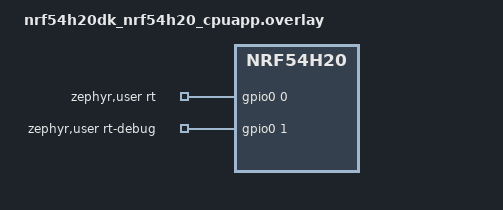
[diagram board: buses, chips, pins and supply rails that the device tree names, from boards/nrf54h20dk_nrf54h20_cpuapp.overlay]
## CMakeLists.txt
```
#
# Copyright (c) 2026 Nordic Semiconductor
#
# SPDX-License-Identifier: LicenseRef-Nordic-5-Clause
#
cmake_minimum_required(VERSION 3.20.0)

find_package(Zephyr REQUIRED HINTS $ENV{ZEPHYR_BASE})
project(rt_framework)

target_include_directories(app PRIVATE include)

# NORDIC SDK APP START
target_sources(app PRIVATE
  src/main.c
  src/rt_framework.c
  src/rt_fastpath.c
)
# NORDIC SDK APP END
```

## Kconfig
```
#
# Copyright (c) 2026 Nordic Semiconductor
#
# SPDX-License-Identifier: LicenseRef-Nordic-5-Clause
#

mainmenu "App-domain RT framework"

config RT_FW_MIN_PERIOD_US
	int "Minimum accepted RT toggle period (us)"
	default 10
	help
	  Lower bound for rt_fw_set_period_us(). Periods below this are rejected
	  rather than clamped. Guards against configuring an extremely high RT
	  tick rate that would saturate the CPU (and, on SoCs where MPSL shares
	  the application core, interfere with radio timing).

config RT_FW_MAX_PERIOD_US
	int "Maximum accepted RT toggle period (us)"
	default 1000000
	help
	  Upper bound for rt_fw_set_period_us(). The RT period is also the
	  control-plane polling interval, so this bounds the worst-case latency
	  of a subsequent stop/reconfigure command to one period.

config RT_FW_EGU_IRQ_PRIO
	int "EGU (data-plane) interrupt priority"
	depends on RT_FW_DATA_PLANE
	default 5
	help
	  Zephyr (non-ZLI) interrupt priority for the EGU interrupt that drains
	  the RT -> Zephyr event ring. Must stay below the ZLI level and is
	  SoC/board dependent. Override it per target if needed.

config RT_FW_DATA_PLANE
	bool "Enable RT -> Zephyr data plane (EGU + event ring)"
	default n
	help
	  When enabled, the RT component pushes events into a single-producer /
	  single-consumer ring in shared RAM and triggers EGU. The EGU interrupt
	  runs at a normal (non-ZLI) Zephyr priority and schedules a work item
	  that drains the ring. Demonstrates the RT -> Zephyr notification path
	  without using Zephyr primitives in the timing-critical path.

config RT_FW_SHARED_DMA_VISIBLE
	bool "Keep the RT event buffer cache-coherent for a DMA/other-master observer"
	depends on RT_FW_DATA_PLANE
	default n
	help
	  Opt-in for the case where the unidirectional RT->Zephyr event payload is
	  also observed by another bus master (a DMA engine or another core),
	  rather than only by the Zephyr threads on the application core.

	  When enabled, the event entries are aligned and padded to whole data
	  cache line(s) and rt_shared.h performs explicit cache maintenance:
	  sys_cache_data_flush_range() after the producer writes an entry and
	  sys_cache_data_invd_range() before the consumer reads it. This is the
	  same cache-maintenance pattern Zephyr's DMM uses for DMA buffers and
	  keeps the buffer coherent without placing it in non-cacheable memory.

	  This option only handles cache coherency. Exposing the buffer to a real
	  external master additionally requires mapping/placing it into that
	  master's address view, e.g. via a devicetree "zephyr,memory-region" with
	  ATTR_MPU_RAM_NOCACHE (board-specific). See the sample README.

	  Leave this disabled for the default app-core ISR <-> thread model: the
	  shared data cache is self-coherent there and ordering barriers alone are
	  sufficient, even on cached SoCs such as nRF54H20. Note that the cache
	  maintenance runs inside the ZLI, so it adds to the RT ISR time budget and
	  is not part of the minimal BLE-coexistence fast path.

config RT_FW_ISR_TEST_LOAD
	bool "Inject an artificial busy-loop load into the RT ZLI ISR"
	default n
	help
	  Adds a controlled busy-loop to the RT zero-latency ISR. Used to study
	  how a longer RT ISR affects BLE timing and to establish the RT ISR time
	  budget. This matters most on SoCs where MPSL/radio ISRs share the
	  application core (e.g. nRF54L), where the ZLI runs at the same NVIC
	  priority as the radio ISRs.

config RT_FW_ISR_TEST_LOAD_CYCLES
	int "Number of NOP iterations for the RT ISR test load"
	depends on RT_FW_ISR_TEST_LOAD
	default 100
	help
	  Number of NOP iterations executed inside the RT ZLI ISR when
	  RT_FW_ISR_TEST_LOAD is enabled.

config RT_FW_DEBUG_PIN
	bool "Drive a debug GPIO high for the duration of the RT ISR"
	default n
	help
	  Drives a second RT-owned GPIO high on ISR entry and low on ISR exit,
	  so the RT ISR execution time can be measured directly with a logic
	  analyzer or oscilloscope.

source "Kconfig.zephyr"
```

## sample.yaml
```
sample:
  description: App-domain real-time framework (TIMER + ZLI + GPIO + control plane)
  name: App-domain RT framework

tests:
  # nRF54L: single-core SoC, MPSL shares the application core. BLE runs as the
  # coexistence load.
  sample.rt_framework:
    sysbuild: false
    build_only: true
    tags:
      - bluetooth
    platform_allow:
      - nrf54lm20dk/nrf54lm20b/cpuapp
    integration_platforms:
      - nrf54lm20dk/nrf54lm20b/cpuapp

  sample.rt_framework.data_plane:
    sysbuild: false
    build_only: true
    tags:
      - bluetooth
    platform_allow:
      - nrf54lm20dk/nrf54lm20b/cpuapp
    integration_platforms:
      - nrf54lm20dk/nrf54lm20b/cpuapp
    extra_configs:
      - CONFIG_RT_FW_DATA_PLANE=y

  # nRF54H20: multi-core SoC with a managed data cache. The RT component still
  # runs only on the application core. The radio/MPSL live on the radio core, so
  # the BLE coexistence load is not built here (single app-core image).
  sample.rt_framework.nrf54h20:
    sysbuild: true
    build_only: true
    platform_allow:
      - nrf54h20dk/nrf54h20/cpuapp
    integration_platforms:
      - nrf54h20dk/nrf54h20/cpuapp

  sample.rt_framework.nrf54h20.data_plane:
    sysbuild: true
    build_only: true
    platform_allow:
      - nrf54h20dk/nrf54h20/cpuapp
    integration_platforms:
      - nrf54h20dk/nrf54h20/cpuapp
    extra_configs:
      - CONFIG_RT_FW_DATA_PLANE=y

  # Build coverage for the explicit cache-maintenance path (sys_cache_*) on a
  # target that has a data cache. Verifies the code and the cache-line
  # alignment asserts compile. Actual cross-master visibility additionally
  # needs board-specific memory placement (see README).
  sample.rt_framework.nrf54h20.dma_visible:
    sysbuild: true
    build_only: true
    platform_allow:
      - nrf54h20dk/nrf54h20/cpuapp
    integration_platforms:
      - nrf54h20dk/nrf54h20/cpuapp
    extra_configs:
      - CONFIG_RT_FW_DATA_PLANE=y
      - CONFIG_RT_FW_SHARED_DMA_VISIBLE=y
```

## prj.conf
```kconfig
#
# Copyright (c) 2026 Nordic Semiconductor
#
# SPDX-License-Identifier: LicenseRef-Nordic-5-Clause
#
CONFIG_NCS_SAMPLES_DEFAULTS=y

# BLE peripheral acts as the "coexistence load" so MPSL/SDC and the radio
# are active while the RT component runs from a zero-latency interrupt.
CONFIG_BT=y
CONFIG_BT_PERIPHERAL=y
CONFIG_BT_DEVICE_NAME="Nordic_RT_FW"
CONFIG_BT_LBS=y
CONFIG_DK_LIBRARY=y

# The RT fast path depends on Zero-latency IRQs.
CONFIG_ZERO_LATENCY_IRQS=y

# Runtime control plane is exposed through the shell.
CONFIG_SHELL=y

CONFIG_SYSTEM_WORKQUEUE_STACK_SIZE=2048

# NOTE: the RT fast path drives TIMER directly through the nrfx HAL and
# installs its own IRQ_DIRECT_CONNECT zero-latency handler.
# The nrfx_timer driver is intentionally NOT enabled, because its
# event dispatcher is incompatible with a minimal ZLI ISR.
```

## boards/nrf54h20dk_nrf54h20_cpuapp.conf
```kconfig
#
# Copyright (c) 2026 Nordic Semiconductor
#
# SPDX-License-Identifier: LicenseRef-Nordic-5-Clause
#
# On nRF54H20 the Bluetooth controller runs on the radio core. This sample is a
# single application-core image, so the optional BLE coexistence load is
# disabled here. The RT mechanism (timer + ZLI + GPIO + control/data plane) is
# exercised on its own. The coexistence scenario is demonstrated on the nRF54L
# target where MPSL shares the application core.
#
CONFIG_BT=n
CONFIG_BT_PERIPHERAL=n
CONFIG_BT_LBS=n
```

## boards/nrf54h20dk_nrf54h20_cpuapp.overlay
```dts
/*
 * Copyright (c) 2026 Nordic Semiconductor
 *
 * SPDX-License-Identifier: LicenseRef-Nordic-5-Clause
 *
 * Resource binding and ownership for the app-domain RT framework on the
 * nRF54H20 application core:
 *  - The RT time base / signaling use global-domain instances owned by the
 *    application core (timer130, egu130).
 *  - On nRF54H20 the Bluetooth controller / MPSL run on the radio core, so the
 *    application-core ZLI does NOT share its NVIC priority with radio ISRs.
 *  - Application-core ownership of a global peripheral driven directly through
 *    the nrfx HAL is expressed with status = "reserved": the build routes the
 *    IRQ and assigns ownership to cpuapp, but instantiates no Zephyr driver.
 */

#include <zephyr/dt-bindings/gpio/gpio.h>

/ {
	aliases {
		rt-timer = &timer130;
		rt-egu = &egu130;
	};

	zephyr,user {
		/* Free P0 connector pins. Wire a probe here to observe the RT path.
		 * Re-map to suit the actual board wiring.
		 */
		rt-gpios = <&gpio0 0 GPIO_ACTIVE_HIGH>;
		rt-debug-gpios = <&gpio0 1 GPIO_ACTIVE_HIGH>;
	};
};

/* Owned by the RT component, driven directly via the nrfx HAL. */
&timer130 {
	status = "reserved";
};

&egu130 {
	status = "reserved";
};

&gpio0 {
	status = "okay";
};
```

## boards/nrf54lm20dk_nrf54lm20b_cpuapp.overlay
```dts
/*
 * Copyright (c) 2026 Nordic Semiconductor
 *
 * SPDX-License-Identifier: LicenseRef-Nordic-5-Clause
 *
 * Resource binding and ownership for the app-domain RT framework on the
 * nRF54LM20 application core.
 *
 * The RT component selects its resources through the aliases / zephyr,user
 * properties below and drives them directly via the nrfx HAL. TIMER20 and
 * EGU20 are therefore kept "disabled" so no Zephyr/nrfx driver claims them:
 * this is the explicit ownership boundary between Zephyr and the RT component.
 *
 * On nRF54L, MPSL reserves TIMER10 and runs its radio ISRs at the single ZLI
 * priority on this same core, so TIMER20 / EGU20 are chosen as free instances.
 * Re-verify the per-SoC MPSL reservations when porting to another target.
 */

#include <zephyr/dt-bindings/gpio/gpio.h>

/ {
	aliases {
		rt-timer = &timer20;
		rt-egu = &egu20;
	};

	zephyr,user {
		/* P1.04: free connector pin toggled by the RT ISR. */
		rt-gpios = <&gpio1 4 GPIO_ACTIVE_HIGH>;
		/* P1.05: optional pin driven high for the RT ISR duration. */
		rt-debug-gpios = <&gpio1 5 GPIO_ACTIVE_HIGH>;
	};
};

&timer20 {
	status = "disabled";
};

&egu20 {
	status = "disabled";
};
```

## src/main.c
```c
/*
 * Copyright (c) 2026 Nordic Semiconductor
 *
 * SPDX-License-Identifier: LicenseRef-Nordic-5-Clause
 */

/*
 * App-domain RT framework - Zephyr application.
 *
 * Brings up:
 *  - the RT component (timer + zero-latency ISR toggling the RT GPIO),
 *  - optionally (CONFIG_BT) a BLE peripheral (LBS) that keeps MPSL/SDC and the
 *    radio active so the ZLI vs MPSL coexistence can be observed on SoCs where
 *    the radio shares the application core,
 *  - a shell command set ("rt ...") that exercises the control plane at
 *    runtime.
 */

#include <errno.h>
#include <zephyr/kernel.h>
#include <zephyr/sys/printk.h>
#include <zephyr/shell/shell.h>

#if defined(CONFIG_BT)
#include <zephyr/bluetooth/bluetooth.h>
#include <zephyr/bluetooth/hci.h>
#include <zephyr/bluetooth/conn.h>
#include <zephyr/bluetooth/uuid.h>
#include <zephyr/bluetooth/gatt.h>
#include <bluetooth/services/lbs.h>
#endif

#include <dk_buttons_and_leds.h>

#include "rt_framework.h"

#define RUN_STATUS_LED         DK_LED1
#define CON_STATUS_LED         DK_LED2
#define RT_EVENT_LED           DK_LED3
#define RUN_LED_BLINK_INTERVAL 1000

#if defined(CONFIG_BT)
#define DEVICE_NAME     CONFIG_BT_DEVICE_NAME
#define DEVICE_NAME_LEN (sizeof(DEVICE_NAME) - 1)

static struct k_work adv_work;

static const struct bt_data ad[] = {
	BT_DATA_BYTES(BT_DATA_FLAGS, (BT_LE_AD_GENERAL | BT_LE_AD_NO_BREDR)),
	BT_DATA(BT_DATA_NAME_COMPLETE, DEVICE_NAME, DEVICE_NAME_LEN),
};

static const struct bt_data sd[] = {
	BT_DATA_BYTES(BT_DATA_UUID128_ALL, BT_UUID_LBS_VAL),
};

static void adv_work_handler(struct k_work *work)
{
	int err;

	ARG_UNUSED(work);

	err = bt_le_adv_start(BT_LE_ADV_CONN_FAST_2, ad, ARRAY_SIZE(ad), sd, ARRAY_SIZE(sd));

	if (err) {
		printk("Advertising failed to start (err %d)\n", err);
		return;
	}

	printk("Advertising successfully started\n");
}

static void advertising_start(void)
{
	k_work_submit(&adv_work);
}

static void connected(struct bt_conn *conn, uint8_t err)
{
	ARG_UNUSED(conn);

	if (err) {
		printk("Connection failed, err 0x%02x %s\n", err, bt_hci_err_to_str(err));
		return;
	}

	printk("Connected\n");
	dk_set_led_on(CON_STATUS_LED);
}

static void disconnected(struct bt_conn *conn, uint8_t reason)
{
	ARG_UNUSED(conn);

	printk("Disconnected, reason 0x%02x %s\n", reason, bt_hci_err_to_str(reason));
	dk_set_led_off(CON_STATUS_LED);
}

static void recycled_cb(void)
{
	advertising_start();
}

BT_CONN_CB_DEFINE(conn_callbacks) = {
	.connected    = connected,
	.disconnected = disconnected,
	.recycled     = recycled_cb,
};

static struct bt_lbs_cb lbs_callbacks;
#endif /* CONFIG_BT */

#if defined(CONFIG_RT_FW_DATA_PLANE)
static bool rt_event_led_state;

static void rt_event_handler(uint32_t type, uint32_t value, uint32_t timestamp)
{
	ARG_UNUSED(type);
	ARG_UNUSED(value);
	ARG_UNUSED(timestamp);
	/* printk("RT event: type=%u value=%u ts=%u\n", type, value, timestamp); */

	rt_event_led_state = !rt_event_led_state;
	dk_set_led(RT_EVENT_LED, rt_event_led_state);
}
#endif

static int cmd_rt_start(const struct shell *sh, size_t argc, char **argv)
{
	ARG_UNUSED(argc);
	ARG_UNUSED(argv);

	rt_fw_enable(true);
	shell_print(sh, "RT path enabled");
	return 0;
}

static int cmd_rt_stop(const struct shell *sh, size_t argc, char **argv)
{
	ARG_UNUSED(argc);
	ARG_UNUSED(argv);

	rt_fw_enable(false);
	shell_print(sh, "RT path disabled");
	return 0;
}

static int cmd_rt_freq(const struct shell *sh, size_t argc, char **argv)
{
	unsigned long period_us;
	int parse_err = 0;
	int err;

	ARG_UNUSED(argc);

	period_us = shell_strtoul(argv[1], 0, &parse_err);
	if (parse_err != 0) {
		shell_error(sh, "Invalid period '%s'", argv[1]);
		return -EINVAL;
	}

	err = rt_fw_set_period_us((uint32_t)period_us);
	if (err) {
		shell_error(sh, "Failed to set period (err %d); allowed range %u..%u us",
			    err, RT_FW_MIN_PERIOD_US, RT_FW_MAX_PERIOD_US);
		return err;
	}

	shell_print(sh, "RT period requested: %lu us (effective within one period)",
		    period_us);
	return 0;
}

static int cmd_rt_status(const struct shell *sh, size_t argc, char **argv)
{
	struct rt_fw_status st;
	int err;

	ARG_UNUSED(argc);
	ARG_UNUSED(argv);

	err = rt_fw_get_status(&st);
	if (err) {
		shell_error(sh, "Failed to read status (err %d)", err);
		return err;
	}

	shell_print(sh, "applied      : %s, %u us (%u ticks)",
		    st.enabled ? "enabled" : "disabled", st.period_us, st.period_ticks);
	shell_print(sh, "requested    : %s, %u us (%u ticks)",
		    st.req_enabled ? "enabled" : "disabled",
		    st.req_period_us, st.req_period_ticks);
	shell_print(sh, "pending      : %s", st.pending ? "yes" : "no");
	shell_print(sh, "command_seq  : %u", st.command_seq);
	shell_print(sh, "ack_seq      : %u", st.ack_seq);
	shell_print(sh, "tick_count   : %u", st.tick_count);
	shell_print(sh, "dropped_evts : %u", st.dropped_events);
	shell_print(sh, "last_error   : %u", st.last_error);
	return 0;
}

SHELL_STATIC_SUBCMD_SET_CREATE(rt_cmds,
	SHELL_CMD(start, NULL, "Enable RT GPIO toggling", cmd_rt_start),
	SHELL_CMD(stop, NULL, "Disable RT GPIO toggling", cmd_rt_stop),
	SHELL_CMD_ARG(freq, NULL, "Set RT period in microseconds: rt freq <us>", cmd_rt_freq, 2, 0),
	SHELL_CMD(status, NULL, "Show RT status/telemetry", cmd_rt_status),
	SHELL_SUBCMD_SET_END
);

SHELL_CMD_REGISTER(rt, &rt_cmds, "App-domain RT framework control plane", NULL);

int main(void)
{
	int blink_status = 0;
	int err;

	printk("Starting app-domain RT framework\n");

	err = dk_leds_init();
	if (err) {
		printk("LEDs init failed (err %d)\n", err);
		return 0;
	}

	err = rt_fw_init();
	if (err) {
		printk("RT framework init failed (err %d)\n", err);
		return 0;
	}

#if defined(CONFIG_RT_FW_DATA_PLANE)
	rt_fw_register_event_cb(rt_event_handler);
#endif

#if defined(CONFIG_BT)
	err = bt_enable(NULL);
	if (err) {
		printk("Bluetooth init failed (err %d)\n", err);
		return 0;
	}

	printk("Bluetooth initialized\n");

	err = bt_lbs_init(&lbs_callbacks);
	if (err) {
		printk("Failed to init LBS (err %d)\n", err);
		return 0;
	}

	k_work_init(&adv_work, adv_work_handler);
	advertising_start();
#else
	printk("BLE coexistence load disabled (CONFIG_BT=n)\n");
#endif

	printk("RT framework ready. Use the 'rt' shell command to control it.\n");

	for (;;) {
		dk_set_led(RUN_STATUS_LED, (++blink_status) % 2);
		k_sleep(K_MSEC(RUN_LED_BLINK_INTERVAL));
	}
}
```

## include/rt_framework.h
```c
/*
 * Copyright (c) 2026 Nordic Semiconductor
 *
 * SPDX-License-Identifier: LicenseRef-Nordic-5-Clause
 */

/*
 * Zephyr-side public API of the app-domain RT framework.
 *
 * This is the control-plane interface that Zephyr-managed code uses to
 * configure the RT component. All calls are non-blocking: they only write to
 * the shared control block and never touch the RT-owned peripherals directly.
 *
 * Thread-safety: the rt_fw_*() functions serialize internally with a mutex, so
 * they may be called from multiple Zephyr threads. They must NOT be called from
 * interrupt context (they take a mutex and are not part of the RT fast path).
 *
 * Command latency: a command becomes effective on the next RT tick. Because the
 * RT period is also the control-plane polling interval, the worst-case latency
 * is one period, which is why the accepted period range is bounded (see
 * rt_fw_set_period_us()).
 */

#ifndef RT_FRAMEWORK_H_
#define RT_FRAMEWORK_H_

#include <stdint.h>
#include <stdbool.h>

#ifdef __cplusplus
extern "C" {
#endif

/* Accepted RT toggle period range, in microseconds. Values outside this range
 * are rejected by rt_fw_set_period_us().
 */
#define RT_FW_MIN_PERIOD_US CONFIG_RT_FW_MIN_PERIOD_US
#define RT_FW_MAX_PERIOD_US CONFIG_RT_FW_MAX_PERIOD_US

/* Snapshot of the RT component state, as observed by Zephyr.
 *
 * The "applied"/effective fields (enabled, period_*) are owned and updated by
 * the RT ISR and reflect the hardware state. The "req_" fields are what Zephyr
 * last requested. While pending is true the request has not been applied yet.
 */
struct rt_fw_status {
	/* Applied / in effect (RT-owned). */
	bool     enabled;
	uint32_t period_us;
	uint32_t period_ticks;

	/* Requested by Zephyr (may differ from applied while pending). */
	bool     req_enabled;
	uint32_t req_period_us;
	uint32_t req_period_ticks;

	/* Handshake / telemetry. */
	bool     pending;        /* command_seq != ack_seq */
	uint32_t command_seq;
	uint32_t ack_seq;
	uint32_t tick_count;
	uint32_t dropped_events; /* data-plane ring overflows */
	uint32_t last_error;
};

/*
 * Initialize the RT component: program TIMER, install the zero-latency ISR
 * and (optionally) set up the EGU data plane. The RT execution context is
 * alive after this call. GPIO toggling is gated by rt_fw_enable().
 */
int rt_fw_init(void);

/* Enable/disable GPIO toggling in the RT path (control plane). */
int rt_fw_enable(bool enable);

/*
 * Set the RT toggle period in microseconds (control plane). The value must be
 * within [RT_FW_MIN_PERIOD_US, RT_FW_MAX_PERIOD_US]. Out-of-range values are
 * rejected with -EINVAL. The change takes effect within one RT period.
 */
int rt_fw_set_period_us(uint32_t period_us);

/* Read back the current RT status/telemetry. */
int rt_fw_get_status(struct rt_fw_status *status);

#if defined(CONFIG_RT_FW_DATA_PLANE)
/* Data-plane callback, invoked from the Zephyr system workqueue. */
typedef void (*rt_fw_event_cb_t)(uint32_t type, uint32_t value, uint32_t timestamp);

/* Register a callback that receives events produced by the RT path. */
int rt_fw_register_event_cb(rt_fw_event_cb_t cb);
#endif

#ifdef __cplusplus
}
#endif

#endif /* RT_FRAMEWORK_H_ */
```

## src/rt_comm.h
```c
/*
 * Copyright (c) 2026 Nordic Semiconductor
 *
 * SPDX-License-Identifier: LicenseRef-Nordic-5-Clause
 */

/*
 * Shared-memory communication structures between the Zephyr application
 * domain and the RT component.
 *
 * Ownership / concurrency model:
 *  - The control block command fields are published with a seqlock: Zephyr
 *    makes command_seq odd (write in progress), writes the command snapshot
 *    (enable + period_ticks), then makes command_seq even again (one greater
 *    than before). The RT ISR only consumes a command when command_seq is even
 *    and differs from ack_seq, reads the snapshot, and re-checks command_seq.
 *    If it changed it retries on the next tick. This guarantees the ISR never
 *    applies a half-written command, which a plain "write fields then bump a
 *    counter" scheme cannot, because the ZLI can preempt the writer at any
 *    point and irq_lock() does not mask it.
 *  - The RT ISR is the single writer of the applied/ack/telemetry fields.
 *    applied_enable/applied_period_ticks reflect what is actually programmed in
 *    hardware, so Zephyr can distinguish a requested command (command_seq !=
 *    ack_seq) from the state in effect.
 *  - The optional event queue is a lock-free single-producer (RT ISR) /
 *    single-consumer (Zephyr) ring.
 *
 * All barriers and (optional) cache maintenance go through rt_shared.h, which
 * is the single place that knows the memory model. Because the RT component is
 * a ZLI on the same core as the Zephyr threads, the shared data cache is
 * self-coherent and ordering barriers alone are sufficient even on cached SoCs
 * (e.g. nRF54H20). Cache maintenance is only engaged for a unidirectional
 * buffer that is additionally DMA-/cross-master-visible
 * (CONFIG_RT_FW_SHARED_DMA_VISIBLE).
 */

#ifndef RT_COMM_H_
#define RT_COMM_H_

#include <stdint.h>
#include <zephyr/toolchain.h>

/*
 * Alignment of DMA-/cross-master-visible payload. Cache-line sized when the
 * opt-in is enabled (so a per-entry invalidate cannot clobber a neighbour),
 * otherwise just word aligned.
 */
#if defined(CONFIG_RT_FW_SHARED_DMA_VISIBLE)
#if defined(CONFIG_DCACHE_LINE_SIZE) && (CONFIG_DCACHE_LINE_SIZE > 0)
#define RT_SHARED_ALIGN CONFIG_DCACHE_LINE_SIZE
#else
#define RT_SHARED_ALIGN 32
#endif
#else
#define RT_SHARED_ALIGN sizeof(uint32_t)
#endif

#ifdef __cplusplus
extern "C" {
#endif

/* The RT-owned GPIOs (toggle output and optional debug pin) are selected from
 * the /zephyr,user devicetree node. See rt_platform.h.
 */

/* Control plane: Zephyr -> RT command/config, RT -> Zephyr status/telemetry. */
struct rt_control_block {
	/* Seqlock-published command (written by Zephyr, read by the RT ISR). */
	volatile uint32_t command_seq;   /* even = stable, odd = write in progress */
	volatile uint32_t enable;        /* requested: 0 = idle, 1 = toggle GPIO */
	volatile uint32_t period_ticks;  /* requested TIMER compare value (CC0) */

	/* Applied/acknowledged state (written by the RT ISR, read by Zephyr). */
	volatile uint32_t ack_seq;              /* command_seq of last applied command */
	volatile uint32_t applied_enable;       /* enable currently in effect */
	volatile uint32_t applied_period_ticks; /* CC0 currently programmed in HW */

	/* RT-owned telemetry/status. */
	volatile uint32_t tick_count;     /* ticks while enabled */
	volatile uint32_t dropped_events; /* data-plane ring overflows (saturating) */
	volatile uint32_t last_error;     /* RT-owned sticky error/status code */
};

#if defined(CONFIG_RT_FW_DATA_PLANE)

/* Must be a power of two. */
#define RT_EVENT_QUEUE_SIZE 16U

enum rt_event_type {
	RT_EVENT_TICK = 1,           /* periodic marker from the RT path */
	RT_EVENT_CONFIG_APPLIED = 2, /* RT applied a new control-plane config */
};

struct rt_event {
	uint32_t type;
	uint32_t value;
	uint32_t timestamp; /* RT tick_count when the event was produced */
} __aligned(RT_SHARED_ALIGN);

/* SPSC ring: RT ISR is the producer (head), Zephyr is the consumer (tail).
 * The entries are aligned so that, under CONFIG_RT_FW_SHARED_DMA_VISIBLE, each
 * one owns whole cache line(s) and the head/tail indices live on a separate
 * line from the payload.
 */
struct rt_event_queue {
	volatile uint32_t head;
	volatile uint32_t tail;
	struct rt_event entries[RT_EVENT_QUEUE_SIZE] __aligned(RT_SHARED_ALIGN);
};

#endif /* CONFIG_RT_FW_DATA_PLANE */

/*
 * The shared instances are defined in rt_fastpath.c, i.e. they are owned by
 * the RT component. The Zephyr side only references them through this header.
 */
extern struct rt_control_block rt_ctrl;

#if defined(CONFIG_RT_FW_DATA_PLANE)
extern struct rt_event_queue rt_evq;
#endif

#ifdef __cplusplus
}
#endif

#endif /* RT_COMM_H_ */
```

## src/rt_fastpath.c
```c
/*
 * Copyright (c) 2026 Nordic Semiconductor
 *
 * SPDX-License-Identifier: LicenseRef-Nordic-5-Clause
 */

/*
 * RT component (fast path) of the app-domain RT framework.
 *
 * This translation unit owns the RT resources, all selected from devicetree
 * (see rt_platform.h):
 *  - rt-timer alias     : periodic time base, driven via the nrfx HAL.
 *  - rt-gpios           : toggled by the zero-latency ISR.
 *  - rt-debug-gpios     : optional ISR-duration debug pin.
 *  - rt-egu alias       : optional RT -> Zephyr signaling (data plane).
 *  - rt_ctrl / rt_evq   : statically allocated shared RAM.
 *
 * The ISR runs as a Zero-Latency Interrupt, i.e. outside Zephyr scheduling and
 * outside the reach of irq_lock(). It must therefore never call Zephyr kernel
 * APIs, logging, or dynamic allocation, and must stay as short as possible.
 * On SoCs where MPSL runs on the same core (e.g. nRF54L), the ZLI shares the
 * highest NVIC priority with the MPSL radio ISRs, which makes a short ISR even
 * more important.
 */

#include <zephyr/kernel.h>
#include <zephyr/irq.h>
#include <soc.h>
#include <cmsis_core.h>

#include <hal/nrf_timer.h>
#include <hal/nrf_gpio.h>
#if defined(CONFIG_RT_FW_DATA_PLANE)
#include <hal/nrf_egu.h>
#endif

#include "rt_comm.h"
#include "rt_shared.h"
#include "rt_platform.h"

/* Target RT time-base rate: 1 MHz -> 1 tick == 1 us, derived per SoC from the
 * timer base frequency (so the prescaler is not hard-coded to one clock).
 */
#define RT_TIMER_TARGET_HZ 1000000U

/* Minimum compare value to keep the periodic interrupt sane. */
#define RT_MIN_PERIOD_TICKS 2U

/* Effective RT time-base configuration, computed once from the SoC clock. */
static uint8_t rt_prescaler;
static uint32_t rt_timer_hz;

static void rt_ensure_clock(void)
{
	uint32_t base_hz;
	uint8_t presc = 0U;

	if (rt_timer_hz != 0U) {
		return;
	}

	base_hz = NRF_TIMER_BASE_FREQUENCY_GET(RT_TIMER);
	while (((base_hz >> presc) > RT_TIMER_TARGET_HZ) && (presc < 9U)) {
		presc++;
	}

	rt_prescaler = presc;
	rt_timer_hz = base_hz >> presc;
}

/* Shared RAM, owned by the RT component (see rt_comm.h). */
struct rt_control_block rt_ctrl;
#if defined(CONFIG_RT_FW_DATA_PLANE)
struct rt_event_queue rt_evq __aligned(RT_SHARED_ALIGN);

#if defined(CONFIG_RT_FW_SHARED_DMA_VISIBLE)
/* When the event payload is treated as DMA-/cross-master-visible, each entry
 * must own whole cache line(s) so a per-entry flush/invalidate cannot clobber a
 * neighbouring entry or the head/tail indices.
 */
BUILD_ASSERT((sizeof(struct rt_event) % RT_SHARED_ALIGN) == 0U,
	     "rt_event size must be a multiple of the cache line size");
BUILD_ASSERT(__alignof__(struct rt_event) >= RT_SHARED_ALIGN,
	     "rt_event must be cache-line aligned");
BUILD_ASSERT(offsetof(struct rt_event_queue, entries) >= RT_SHARED_ALIGN,
	     "event entries must not share a cache line with head/tail");
#endif
#endif

#if defined(CONFIG_RT_FW_DATA_PLANE)
/* Single-producer push from the RT ISR: drops the event if the ring is full. */
static inline void rt_push_event(uint32_t type, uint32_t value)
{
	uint32_t head = rt_evq.head;
	uint32_t next = (head + 1U) & (RT_EVENT_QUEUE_SIZE - 1U);

	if (next == rt_evq.tail) {
		/* Ring full: drop and count it (saturating) so the consumer can
		 * see the scale of the overflow, not just that one happened.
		 */
		if (rt_ctrl.dropped_events != UINT32_MAX) {
			rt_ctrl.dropped_events++;
		}
		return;
	}

	rt_evq.entries[head].type = type;
	rt_evq.entries[head].value = value;
	rt_evq.entries[head].timestamp = rt_ctrl.tick_count;

	/* The entry is a unidirectional payload (RT writes, Zephyr reads), so it
	 * is safe to flush it towards a DMA/other-master observer when that
	 * opt-in is enabled. On the default same-core path this is just the
	 * release barrier.
	 */
	rt_shared_dma_flush(&rt_evq.entries[head], sizeof(rt_evq.entries[head]));
	rt_shared_release();
	rt_evq.head = next;

	nrf_egu_task_trigger(RT_EGU, NRF_EGU_TASK_TRIGGER0);
}
#endif /* CONFIG_RT_FW_DATA_PLANE */

/*
 * Consume a pending control-plane command at a tick boundary using the seqlock
 * protocol (see rt_comm.h). Reads a consistent {enable, period_ticks} snapshot,
 * programs the hardware and publishes the applied state. Returns true when a
 * command was applied (so the caller acks exactly that command_seq).
 *
 * If the writer is mid-update (odd command_seq) or the snapshot changes under
 * us, nothing is applied and the command stays pending for the next tick. The
 * ISR therefore never spins.
 */
static inline bool rt_consume_command(void)
{
	uint32_t seq = rt_ctrl.command_seq;
	uint32_t enable;
	uint32_t ticks;

	/* Odd => writer in progress; nothing new => already up to date. */
	if ((seq & 1U) != 0U || seq == rt_ctrl.ack_seq) {
		return false;
	}

	/* Acquire: observing the even command_seq happens-before reading the
	 * command payload it published.
	 */
	rt_shared_acquire();
	enable = rt_ctrl.enable;
	ticks = rt_ctrl.period_ticks;
	rt_shared_acquire();

	/* The snapshot is only valid if the writer did not touch the command
	 * between the two reads of command_seq.
	 */
	if (rt_ctrl.command_seq != seq) {
		return false;
	}

	if (ticks < RT_MIN_PERIOD_TICKS) {
		ticks = RT_MIN_PERIOD_TICKS;
	}

	/* New compare value takes effect on the next compare cycle. */
	nrf_timer_cc_set(RT_TIMER, NRF_TIMER_CC_CHANNEL0, ticks);

	if (enable == 0U) {
		/* Drive the output to a defined idle level when disabled. */
		nrf_gpio_pin_clear(RT_GPIO_ABS);
	}

	/* Publish the state actually in effect, then ack this exact command. */
	rt_ctrl.applied_period_ticks = ticks;
	rt_ctrl.applied_enable = enable;
	rt_shared_release();
	rt_ctrl.ack_seq = seq;

#if defined(CONFIG_RT_FW_DATA_PLANE)
	rt_push_event(RT_EVENT_CONFIG_APPLIED, ticks);
#endif
	return true;
}

/*
 * Zero-latency timer ISR. The TIMER COMPARE0 short auto-clears the counter,
 * so this fires periodically. The body is intentionally tiny.
 */
ISR_DIRECT_DECLARE(rt_fastpath_isr)
{
	if (nrf_timer_event_check(RT_TIMER, NRF_TIMER_EVENT_COMPARE0)) {
		nrf_timer_event_clear(RT_TIMER, NRF_TIMER_EVENT_COMPARE0);

#if defined(CONFIG_RT_FW_DEBUG_PIN)
		nrf_gpio_pin_set(RT_DEBUG_ABS);
#endif

		/* Control plane: apply at most one pending command per tick. */
		(void)rt_consume_command();

		/* Real-time work, gated by the state actually applied (not the
		 * requested one, which may still be mid-publish).
		 */
		if (rt_ctrl.applied_enable) {
			nrf_gpio_pin_toggle(RT_GPIO_ABS);
			rt_ctrl.tick_count++;
#if defined(CONFIG_RT_FW_DATA_PLANE)
			rt_push_event(RT_EVENT_TICK, rt_ctrl.tick_count);
#endif
		}

#if defined(CONFIG_RT_FW_ISR_TEST_LOAD)
		for (volatile uint32_t i = 0; i < CONFIG_RT_FW_ISR_TEST_LOAD_CYCLES; i++) {
			__NOP();
		}
#endif

#if defined(CONFIG_RT_FW_DEBUG_PIN)
		nrf_gpio_pin_clear(RT_DEBUG_ABS);
#endif
	}

	/* ZLI handlers never request a reschedule. */
	return 0;
}

uint32_t rt_fastpath_us_to_ticks(uint32_t us)
{
	uint64_t ticks;

	rt_ensure_clock();
	ticks = ((uint64_t)us * rt_timer_hz) / 1000000ULL;

	if (ticks < RT_MIN_PERIOD_TICKS) {
		ticks = RT_MIN_PERIOD_TICKS;
	}
	if (ticks > UINT32_MAX) {
		ticks = UINT32_MAX;
	}

	return (uint32_t)ticks;
}

uint32_t rt_fastpath_ticks_to_us(uint32_t ticks)
{
	uint64_t us;

	rt_ensure_clock();
	us = ((uint64_t)ticks * 1000000ULL) / rt_timer_hz;

	if (us > UINT32_MAX) {
		us = UINT32_MAX;
	}

	return (uint32_t)us;
}

void rt_fastpath_init(uint32_t initial_period_ticks)
{
	/* RT-owned GPIO outputs. */
	nrf_gpio_cfg_output(RT_GPIO_ABS);
	nrf_gpio_pin_clear(RT_GPIO_ABS);
#if defined(CONFIG_RT_FW_DEBUG_PIN)
	nrf_gpio_cfg_output(RT_DEBUG_ABS);
	nrf_gpio_pin_clear(RT_DEBUG_ABS);
#endif

	/* The applied state mirrors the hardware programmed below: the timer
	 * runs at initial_period_ticks but output toggling is off until enabled.
	 */
	rt_ctrl.applied_enable = 0U;
	rt_ctrl.applied_period_ticks = initial_period_ticks;

	/* RT-owned time base, configured directly through the HAL. */
	rt_ensure_clock();
	nrf_timer_task_trigger(RT_TIMER, NRF_TIMER_TASK_STOP);
	nrf_timer_task_trigger(RT_TIMER, NRF_TIMER_TASK_CLEAR);
	nrf_timer_mode_set(RT_TIMER, NRF_TIMER_MODE_TIMER);
	nrf_timer_bit_width_set(RT_TIMER, NRF_TIMER_BIT_WIDTH_32);
	nrf_timer_prescaler_set(RT_TIMER, rt_prescaler);
	nrf_timer_cc_set(RT_TIMER, NRF_TIMER_CC_CHANNEL0, initial_period_ticks);
	nrf_timer_shorts_enable(RT_TIMER, NRF_TIMER_SHORT_COMPARE0_CLEAR_MASK);
	nrf_timer_event_clear(RT_TIMER, NRF_TIMER_EVENT_COMPARE0);
	nrf_timer_int_enable(RT_TIMER, NRF_TIMER_INT_COMPARE0_MASK);

	/* Install the timer interrupt as a Zero-Latency IRQ. The priority
	 * argument is overridden by Zephyr to the ZLI level.
	 */
	IRQ_DIRECT_CONNECT(RT_TIMER_IRQN, 0, rt_fastpath_isr, IRQ_ZERO_LATENCY);
	irq_enable(RT_TIMER_IRQN);

	/* The RT execution context is always alive after init. The timer runs
	 * and the ISR polls the control plane every tick. GPIO toggling itself
	 * is gated by rt_ctrl.enable.
	 */
	nrf_timer_task_trigger(RT_TIMER, NRF_TIMER_TASK_START);
}
```

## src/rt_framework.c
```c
/*
 * Copyright (c) 2026 Nordic Semiconductor
 *
 * SPDX-License-Identifier: LicenseRef-Nordic-5-Clause
 */

/*
 * Zephyr-side control plane of the app-domain RT framework.
 *
 * These functions implement the non-blocking seq/ack handshake with the RT
 * component: write the parameters, issue a memory barrier, then bump
 * command_seq. The RT ISR observes the change and applies it at a tick
 * boundary, copying command_seq into ack_seq.
 *
 * When the data plane is enabled, this file also owns the EGU interrupt
 * (normal Zephyr priority) that drains the RT -> Zephyr event ring into the
 * system workqueue.
 */

#include <zephyr/kernel.h>
#include <zephyr/logging/log.h>
#include <errno.h>

#include "rt_comm.h"
#include "rt_shared.h"
#include "rt_framework.h"

#if defined(CONFIG_RT_FW_DATA_PLANE)
#include <zephyr/irq.h>
#include <soc.h>
#include <hal/nrf_egu.h>
#include "rt_platform.h"
#endif

LOG_MODULE_REGISTER(rt_framework, LOG_LEVEL_INF);

/* Default toggle period: 500 ms -> visible blink and easy scope capture. */
#define RT_FW_DEFAULT_PERIOD_US 500000U

/* Implemented in rt_fastpath.c (RT component). */
void rt_fastpath_init(uint32_t initial_period_ticks);
uint32_t rt_fastpath_us_to_ticks(uint32_t us);
uint32_t rt_fastpath_ticks_to_us(uint32_t ticks);

/*
 * Zephyr-private "desired state" shadow. The public API mutates this and then
 * publishes a complete, consistent command snapshot to the RT component. Keeping
 * the desired state here (instead of reading it back from the shared block)
 * means a single API call always publishes a coherent {enable, period} pair.
 *
 * rt_lock serializes the Zephyr-side writers so the seqlock writer sequence and
 * the desired shadow are never corrupted by concurrent callers. The lock does
 * NOT (and cannot) exclude the ZLI. The seqlock alone makes the command
 * publish-safe against the RT ISR.
 */
static K_MUTEX_DEFINE(rt_lock);

static struct {
	uint32_t enable;
	uint32_t period_us;
	uint32_t period_ticks;
} rt_desired = {
	.enable = 0U,
	.period_us = RT_FW_DEFAULT_PERIOD_US,
};

/*
 * Publish rt_desired to the RT component using the seqlock protocol: make
 * command_seq odd (write in progress), write the snapshot, then make it even
 * again. The RT ISR only consumes a command observed with an even command_seq
 * that is stable across the read. Caller must hold rt_lock.
 */
static void rt_publish(void)
{
	uint32_t seq = rt_ctrl.command_seq;

	rt_ctrl.command_seq = seq + 1U; /* odd: write in progress */
	rt_shared_release();

	rt_ctrl.enable = rt_desired.enable;
	rt_ctrl.period_ticks = rt_desired.period_ticks;
	rt_shared_release();

	rt_ctrl.command_seq = seq + 2U; /* even: snapshot published */
}

#if defined(CONFIG_RT_FW_DATA_PLANE)

#define RT_FW_EGU_IRQ_PRIO CONFIG_RT_FW_EGU_IRQ_PRIO

static rt_fw_event_cb_t event_cb;
static struct k_work event_work;

static void event_work_handler(struct k_work *work)
{
	ARG_UNUSED(work);

	while (rt_evq.tail != rt_evq.head) {
		uint32_t tail = rt_evq.tail;
		struct rt_event evt;

		/* Acquire paired with the producer's release (entry written,
		 * release, then head advanced). Observing the updated head must
		 * happen-before reading the entry contents, otherwise a stale
		 * entry could be read on a weakly-ordered memory system.
		 */
		rt_shared_acquire();

		/* Drop stale cache lines for the entry if it is DMA-/cross-
		 * master-visible. No-op on the default same-core path. Safe
		 * because the entry is written only by the producer.
		 */
		rt_shared_dma_invalidate(&rt_evq.entries[tail], sizeof(rt_evq.entries[tail]));

		evt = rt_evq.entries[tail];

		/* Release: the entry read must complete before the new tail
		 * becomes visible to the producer, otherwise the RT ISR could
		 * overwrite the slot while it is still being read.
		 */
		rt_shared_release();

		rt_evq.tail = (tail + 1U) & (RT_EVENT_QUEUE_SIZE - 1U);

		if (event_cb != NULL) {
			event_cb(evt.type, evt.value, evt.timestamp);
		}
	}
}

static void rt_egu_isr(const void *arg)
{
	ARG_UNUSED(arg);

	nrf_egu_event_clear(RT_EGU, NRF_EGU_EVENT_TRIGGERED0);
	k_work_submit(&event_work);
}

static void rt_dataplane_init(void)
{
	rt_evq.head = 0;
	rt_evq.tail = 0;

	k_work_init(&event_work, event_work_handler);

	nrf_egu_event_clear(RT_EGU, NRF_EGU_EVENT_TRIGGERED0);
	nrf_egu_int_enable(RT_EGU, NRF_EGU_INT_TRIGGERED0);

	IRQ_CONNECT(RT_EGU_IRQN, RT_FW_EGU_IRQ_PRIO, rt_egu_isr, NULL, 0);
	irq_enable(RT_EGU_IRQN);
}

int rt_fw_register_event_cb(rt_fw_event_cb_t cb)
{
	event_cb = cb;
	return 0;
}

#endif /* CONFIG_RT_FW_DATA_PLANE */

int rt_fw_init(void)
{
	rt_desired.enable = 0U;
	rt_desired.period_us = RT_FW_DEFAULT_PERIOD_US;
	rt_desired.period_ticks = rt_fastpath_us_to_ticks(RT_FW_DEFAULT_PERIOD_US);

	rt_ctrl.command_seq = 0;
	rt_ctrl.ack_seq = 0;
	rt_ctrl.enable = 0;
	rt_ctrl.period_ticks = rt_desired.period_ticks;
	rt_ctrl.tick_count = 0;
	rt_ctrl.dropped_events = 0;
	rt_ctrl.last_error = 0;
	rt_shared_release();

#if defined(CONFIG_RT_FW_DATA_PLANE)
	rt_dataplane_init();
#endif

	rt_fastpath_init(rt_desired.period_ticks);

	LOG_INF("RT framework initialized (timer ZLI + RT GPIO, period %u us)",
		rt_desired.period_us);
	return 0;
}

int rt_fw_enable(bool enable)
{
	k_mutex_lock(&rt_lock, K_FOREVER);
	rt_desired.enable = enable ? 1U : 0U;
	rt_publish();
	k_mutex_unlock(&rt_lock);
	return 0;
}

int rt_fw_set_period_us(uint32_t period_us)
{
	if (period_us < RT_FW_MIN_PERIOD_US || period_us > RT_FW_MAX_PERIOD_US) {
		/* Reject out-of-range periods rather than silently clamping: the
		 * period is also the control-plane polling interval, so an
		 * unbounded value would make stop/reconfigure unresponsive.
		 */
		return -EINVAL;
	}

	k_mutex_lock(&rt_lock, K_FOREVER);
	rt_desired.period_us = period_us;
	rt_desired.period_ticks = rt_fastpath_us_to_ticks(period_us);
	rt_publish();
	k_mutex_unlock(&rt_lock);
	return 0;
}

int rt_fw_get_status(struct rt_fw_status *status)
{
	if (status == NULL) {
		return -EINVAL;
	}

	k_mutex_lock(&rt_lock, K_FOREVER);

	/* Requested state: what Zephyr last asked for. */
	status->req_period_us = rt_desired.period_us;
	status->req_period_ticks = rt_desired.period_ticks;
	status->req_enabled = (rt_desired.enable != 0U);

	/* Applied state: what the RT path has actually programmed (RT-owned). */
	rt_shared_acquire();
	status->enabled = (rt_ctrl.applied_enable != 0U);
	status->period_ticks = rt_ctrl.applied_period_ticks;
	status->period_us = rt_fastpath_ticks_to_us(rt_ctrl.applied_period_ticks);

	/* A command is still pending until the RT ISR acks the latest seq. */
	status->command_seq = rt_ctrl.command_seq;
	status->ack_seq = rt_ctrl.ack_seq;
	status->pending = (rt_ctrl.command_seq != rt_ctrl.ack_seq);

	status->tick_count = rt_ctrl.tick_count;
	status->dropped_events = rt_ctrl.dropped_events;
	status->last_error = rt_ctrl.last_error;

	k_mutex_unlock(&rt_lock);
	return 0;
}
```

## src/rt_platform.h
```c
/*
 * Copyright (c) 2026 Nordic Semiconductor
 *
 * SPDX-License-Identifier: LicenseRef-Nordic-5-Clause
 */

/*
 * Platform binding for the RT component.
 *
 * The RT-owned resources (time base, signaling peripheral, GPIOs) are selected
 * from devicetree, not hard-coded, so porting the framework to another SoC is a
 * board-overlay change rather than a source change:
 *
 *   aliases {
 *       rt-timer = <&timerXX>;   // RT time base (status = "disabled" for Zephyr)
 *       rt-egu   = <&eguXX>;     // only needed for the data plane
 *   };
 *   zephyr,user {
 *       rt-gpios       = <&gpioX pin flags>;   // toggled by the RT ISR
 *       rt-debug-gpios = <&gpioX pin flags>;   // optional ISR-duration pin
 *   };
 *
 * The peripherals are accessed directly through the nrfx HAL, so we only take
 * the register base and IRQ line from devicetree. The nodes are kept out of
 * Zephyr's reach (status = "disabled" on nRF54L, or "reserved" on nRF54H20
 * where the app core owns a global instance) so no Zephyr driver claims them.
 */

#ifndef RT_PLATFORM_H_
#define RT_PLATFORM_H_

#include <zephyr/devicetree.h>
#include <zephyr/dt-bindings/gpio/gpio.h>
#include <soc.h>
#include <hal/nrf_timer.h>
#if defined(CONFIG_RT_FW_DATA_PLANE)
#include <hal/nrf_egu.h>
#endif

/* RT time base: chosen via the "rt-timer" devicetree alias. */
#define RT_TIMER_NODE DT_ALIAS(rt_timer)
BUILD_ASSERT(DT_NODE_EXISTS(RT_TIMER_NODE),
	     "rt_framework: define an 'rt-timer' alias in the board overlay");
#define RT_TIMER      ((NRF_TIMER_Type *)DT_REG_ADDR(RT_TIMER_NODE))
#define RT_TIMER_IRQN DT_IRQN(RT_TIMER_NODE)

/* RT-owned GPIOs, taken from the /zephyr,user node and resolved to an absolute
 * pin number usable with the GPIO HAL.
 */
#define RT_USER_NODE DT_PATH(zephyr_user)
#define RT_GPIO_ABS  NRF_DT_GPIOS_TO_PSEL(RT_USER_NODE, rt_gpios)
/* The RT ISR drives the pin level directly through the GPIO HAL, so only an
 * active-high output is honoured (the DT polarity/pull flags are not applied).
 */
BUILD_ASSERT((DT_GPIO_FLAGS(RT_USER_NODE, rt_gpios) & GPIO_ACTIVE_LOW) == 0,
	     "rt_framework: rt-gpios must be active-high (HAL path ignores flags)");
#if defined(CONFIG_RT_FW_DEBUG_PIN)
#define RT_DEBUG_ABS NRF_DT_GPIOS_TO_PSEL(RT_USER_NODE, rt_debug_gpios)
BUILD_ASSERT((DT_GPIO_FLAGS(RT_USER_NODE, rt_debug_gpios) & GPIO_ACTIVE_LOW) == 0,
	     "rt_framework: rt-debug-gpios must be active-high (HAL path ignores flags)");
#endif

#if defined(CONFIG_RT_FW_DATA_PLANE)
/* RT signaling peripheral for the data plane: the "rt-egu" alias. */
#define RT_EGU_NODE DT_ALIAS(rt_egu)
BUILD_ASSERT(DT_NODE_EXISTS(RT_EGU_NODE),
	     "rt_framework: define an 'rt-egu' alias when the data plane is enabled");
#define RT_EGU      ((NRF_EGU_Type *)DT_REG_ADDR(RT_EGU_NODE))
#define RT_EGU_IRQN DT_IRQN(RT_EGU_NODE)
#endif

#endif /* RT_PLATFORM_H_ */
```

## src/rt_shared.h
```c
/*
 * Copyright (c) 2026 Nordic Semiconductor
 *
 * SPDX-License-Identifier: LicenseRef-Nordic-5-Clause
 */

/*
 * Single point of truth for the shared-memory concurrency model of the
 * app-domain RT framework.
 *
 * The framework's execution model is fixed: the RT component is a zero-latency
 * interrupt (ZLI) running on the same application core as the Zephyr threads.
 * The control plane and data plane are therefore plain ISR <-> thread traffic
 * on one core. Because both contexts share the same data cache, that cache is
 * self-coherent and ordering barriers alone are sufficient, even on SoCs with
 * a data cache such as nRF54H20.
 *
 * Cache maintenance is required only if a *unidirectional* shared buffer is
 * additionally exposed to another bus master (a DMA engine or another core).
 * That case is opt-in (CONFIG_RT_FW_SHARED_DMA_VISIBLE) and is wired through the
 * rt_shared_dma_*() helpers below. It must NOT be used on a bidirectional
 * structure (e.g. the control block, where the ISR both reads commands and
 * writes status) because cache invalidation there is destructive.
 *
 * Keeping all barriers and cache operations here means the memory model lives
 * in exactly one place. The rest of the framework never calls __DMB() or the
 * cache API directly.
 */

#ifndef RT_SHARED_H_
#define RT_SHARED_H_

#include <stddef.h>
#include <cmsis_core.h>

#if defined(CONFIG_RT_FW_SHARED_DMA_VISIBLE)
#include <zephyr/cache.h>
#endif

#ifdef __cplusplus
extern "C" {
#endif

/*
 * Release barrier (producer). All prior writes to the shared region are made
 * visible before the subsequent "publish" store (a sequence number or ring
 * index). Pair with rt_shared_acquire() on the consumer.
 */
static inline void rt_shared_release(void)
{
	__DMB();
}

/*
 * Acquire barrier (consumer). The observation of a published sequence number /
 * ring index happens-before the subsequent reads of the shared payload.
 */
static inline void rt_shared_acquire(void)
{
	__DMB();
}

/*
 * Push a unidirectional payload this context just wrote out towards other
 * observers. No-op unless the region is DMA-/cross-master-visible. Call after
 * writing the payload and before the release + publish.
 *
 * @p addr must be cache-line aligned and @p len a multiple of the cache line
 * size when the opt-in is enabled (see CONFIG_RT_FW_SHARED_DMA_VISIBLE).
 */
static inline void rt_shared_dma_flush(void *addr, size_t len)
{
#if defined(CONFIG_RT_FW_SHARED_DMA_VISIBLE)
	(void)sys_cache_data_flush_range(addr, len);
#else
	(void)addr;
	(void)len;
#endif
}

/*
 * Drop any stale cache lines for a unidirectional payload another master may
 * have written, before this context reads it. No-op unless the region is
 * DMA-/cross-master-visible. Call after the acquire and before reading.
 *
 * Invalidation is destructive, so only use this on a buffer that this context
 * does not itself write (see the file header).
 */
static inline void rt_shared_dma_invalidate(void *addr, size_t len)
{
#if defined(CONFIG_RT_FW_SHARED_DMA_VISIBLE)
	(void)sys_cache_data_invd_range(addr, len);
#else
	(void)addr;
	(void)len;
#endif
}

#ifdef __cplusplus
}
#endif

#endif /* RT_SHARED_H_ */
```
